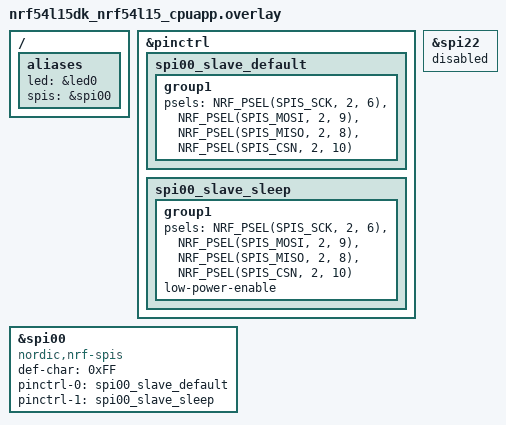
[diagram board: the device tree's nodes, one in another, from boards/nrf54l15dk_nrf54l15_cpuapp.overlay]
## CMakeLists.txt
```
#
# Copyright (c) 2025 Nordic Semiconductor ASA
# SPDX-License-Identifier: LicenseRef-Nordic-5-Clause
#

cmake_minimum_required(VERSION 3.20.0)

find_package(Zephyr REQUIRED HINTS $ENV{ZEPHYR_BASE})

if(NOT SYSBUILD)
  message(FATAL_ERROR
    " This is a multi-image application that should be built using sysbuild.\n"
    " Add --sysbuild argument to west build command to prepare all the images."
  )
endif()

project(NRF54l15)

# Windows Device Guard workaround:
# Build static libraries with "ar qcs" and skip the separate ranlib step.
# This avoids calling arm-zephyr-eabi-ranlib.exe when it is policy-blocked.
if(WIN32)
  set(CMAKE_C_ARCHIVE_CREATE
      "<CMAKE_AR> qcs <TARGET> <LINK_FLAGS> <OBJECTS>"
      CACHE STRING "Create C static archive without separate ranlib" FORCE)
  set(CMAKE_CXX_ARCHIVE_CREATE
      "<CMAKE_AR> qcs <TARGET> <LINK_FLAGS> <OBJECTS>"
      CACHE STRING "Create CXX static archive without separate ranlib" FORCE)
  set(CMAKE_ASM_ARCHIVE_CREATE
      "<CMAKE_AR> qcs <TARGET> <LINK_FLAGS> <OBJECTS>"
      CACHE STRING "Create ASM static archive without separate ranlib" FORCE)

  set(CMAKE_C_ARCHIVE_FINISH "" CACHE STRING "Skip C ranlib step" FORCE)
  set(CMAKE_CXX_ARCHIVE_FINISH "" CACHE STRING "Skip CXX ranlib step" FORCE)
  set(CMAKE_ASM_ARCHIVE_FINISH "" CACHE STRING "Skip ASM ranlib step" FORCE)
endif()

target_sources(app PRIVATE
  ${CMAKE_CURRENT_SOURCE_DIR}/src/main.c
)
```

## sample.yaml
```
common:
  sysbuild: true
  depends_on: spi

sample:
  name: SPI wakeup sample
tests:
  nrf.extended.sample.drivers.spis.wakeup:
    tags:
      - ci_samples_zephyr_boards_nordic_spis_wakeup
      - spi
      - ppk_power_measure
    platform_allow:
      - nrf54h20dk/nrf54h20/cpuapp
      - nrf54l15dk/nrf54l15/cpuapp
    integration_platforms:
      - nrf54h20dk/nrf54h20/cpuapp
      - nrf54l15dk/nrf54l15/cpuapp
    harness: pytest
    harness_config:
      fixture: spi_loopback
      pytest_root:
        - "${CUSTOM_ROOT_TEST_DIR}/test_measure_power_consumption.py::test_measure_and_data_dump_spis_wakeup"
```

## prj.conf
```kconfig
CONFIG_SPI=y
CONFIG_SPI_SLAVE=y
CONFIG_GPIO=y

# Bring-up/debug profile first. Re-enable PM once SPI link is validated.
CONFIG_PM=n
CONFIG_PM_DEVICE=n
CONFIG_PM_DEVICE_RUNTIME=n

CONFIG_ASSERT=y

CONFIG_PRINTK=y
CONFIG_LOG=y
CONFIG_LOG_MODE_IMMEDIATE=y
CONFIG_LOG_DEFAULT_LEVEL=3
CONFIG_CONSOLE=y
CONFIG_SERIAL=y

# Route console/log output over SEGGER RTT (instead of UART)
CONFIG_USE_SEGGER_RTT=y
CONFIG_RTT_CONSOLE=y
CONFIG_UART_CONSOLE=n
CONFIG_LOG_BACKEND_RTT=y
CONFIG_LOG_BACKEND_UART=n
```

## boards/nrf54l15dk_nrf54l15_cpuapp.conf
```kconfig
# nRF54L15 DK CPUAPP board-specific config for SPI slave bring-up.
# Keep empty for now; app-level settings are in prj.conf.
```

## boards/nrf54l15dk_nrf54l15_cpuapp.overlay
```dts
/*
 * nRF54L15 DK CPUAPP SPI-slave overlay — HSSPI (SPIS00, P2 port, up to 32 MHz).
 * Wire to Pico: GPIO18(SCK)→P2.06, GPIO19(MOSI)→P2.09, GPIO20(MISO)→P2.08, GPIO22(CS)→P2.10
 */

/ {
	aliases {
		led = &led0;
		spis = &spi00;               /* switched from spi22 to HSSPI instance */
		/delete-property/ led1;
		/delete-property/ mcuboot-button0;
	};
};

/delete-node/ &led1;

&pinctrl {
	spi00_slave_default: spi00_slave_default {
		group1 {
			psels = <NRF_PSEL(SPIS_SCK,  2, 6)>,
				<NRF_PSEL(SPIS_MOSI, 2, 9)>,
				<NRF_PSEL(SPIS_MISO, 2, 8)>,
				<NRF_PSEL(SPIS_CSN,  2, 10)>;
		};
	};

	spi00_slave_sleep: spi00_slave_sleep {
		group1 {
			psels = <NRF_PSEL(SPIS_SCK,  2, 6)>,
				<NRF_PSEL(SPIS_MOSI, 2, 9)>,
				<NRF_PSEL(SPIS_MISO, 2, 8)>,
				<NRF_PSEL(SPIS_CSN,  2, 10)>;
			low-power-enable;
		};
	};
};

&spi00 {
	compatible = "nordic,nrf-spis";
	status = "okay";
	/delete-property/ cs-gpios;
	/delete-property/ rx-delay-supported;
	/delete-property/ rx-delay;
	def-char = <0xFF>;
	pinctrl-0 = <&spi00_slave_default>;
	pinctrl-1 = <&spi00_slave_sleep>;
	pinctrl-names = "default", "sleep";
	/delete-node/ mx25r6435f@0;
};

/* Disable the old spi22 slave to release P1 pins */
&spi22 {
	status = "disabled";
};
```

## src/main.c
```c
/*
 * Copyright (c) 2025 Nordic Semiconductor ASA
 * SPDX-License-Identifier: Apache-2.0
 */

#include <zephyr/kernel.h>
#include <zephyr/logging/log.h>
#include <zephyr/drivers/spi.h>
#include <zephyr/drivers/gpio.h>
#include <string.h>

#define NRF_BENCH_MODE  // Compile with this defined to enable the SPI slave test mode that logs transfer stats and button events; undefine for production build without logging and NRF event handling

#define BUF_SIZE 4096

static const struct device *spis_dev = DEVICE_DT_GET(DT_ALIAS(spis));
static const struct spi_config spis_config = {.operation = SPI_OP_MODE_SLAVE | SPI_WORD_SET(8) | SPI_MODE_CPHA};

#ifdef NRF_BENCH_MODE

#define BUTTON_DEBOUNCE_SAMPLES 4
#define BUTTON_RETRIGGER_GUARD_MS 350

static const struct gpio_dt_spec led = GPIO_DT_SPEC_GET(DT_ALIAS(led), gpios);
static const struct gpio_dt_spec btn0 = GPIO_DT_SPEC_GET(DT_ALIAS(sw0), gpios);
static const struct gpio_dt_spec btn1 = GPIO_DT_SPEC_GET(DT_ALIAS(sw1), gpios);
static const struct gpio_dt_spec btn2 = GPIO_DT_SPEC_GET(DT_ALIAS(sw2), gpios);
static const struct gpio_dt_spec btn3 = GPIO_DT_SPEC_GET(DT_ALIAS(sw3), gpios);

LOG_MODULE_REGISTER(spi_slave_test, LOG_LEVEL_INF);

static uint8_t tx_buffer[BUF_SIZE];
static uint8_t rx_buffer[BUF_SIZE];
static uint8_t pending_button_events;
static uint8_t debounced_button_state;
static uint8_t button_change_count[4];
static int64_t button_next_press_ok_ms[4];
static uint32_t transfer_count;
static uint32_t error_count;
static uint32_t zero_frame_count;
static uint32_t short_frame_count;
static uint32_t marker_inject_count;
static uint8_t last_rx0;
static uint8_t last_rx1;
static uint8_t last_rx2;
static uint8_t last_rx3;
static uint8_t last_rx13;
static uint8_t last_rx14;

static void fill_tx_pattern(void)
{
	for (size_t i = 0; i < BUF_SIZE; ++i) {
		tx_buffer[i] = (i & 1u) ? 0xA5 : 0x5A;
	}
}

static uint8_t xor_checksum(const uint8_t *buf, size_t len)
{
	uint8_t x = 0;
	for (size_t i = 0; i < len; ++i) {
		x ^= buf[i];
	}
	return x;
}

static bool buffer_all_value(const uint8_t *buf, size_t len, uint8_t value)
{
	for (size_t i = 0; i < len; ++i) {
		if (buf[i] != value) {
			return false;
		}
	}
	return true;
}

static uint8_t read_button_state(void)
{
	uint8_t state = 0;
	/* Active-low buttons: pressed => bit set in returned mask. */
	if (gpio_pin_get_dt(&btn0) == 0) state |= BIT(0);
	if (gpio_pin_get_dt(&btn1) == 0) state |= BIT(1);
	if (gpio_pin_get_dt(&btn2) == 0) state |= BIT(2);
	if (gpio_pin_get_dt(&btn3) == 0) state |= BIT(3);
	return state;
}

static void update_button_events(void)
{
	uint8_t raw = read_button_state();
	uint8_t rising_press = 0;
	int64_t now_ms = k_uptime_get();

	for (uint8_t i = 0; i < 4; ++i) {
		uint8_t bit = BIT(i);
		bool raw_pressed = (raw & bit) != 0;
		bool stable_pressed = (debounced_button_state & bit) != 0;

		if (raw_pressed == stable_pressed) {
			button_change_count[i] = 0;
			continue;
		}

		if (button_change_count[i] < 0xFF) {
			button_change_count[i]++;
		}
		if (button_change_count[i] < BUTTON_DEBOUNCE_SAMPLES) {
			continue;
		}

		button_change_count[i] = 0;
		if (raw_pressed) {
			debounced_button_state |= bit;
			if (now_ms >= button_next_press_ok_ms[i]) {
				rising_press |= bit;
				button_next_press_ok_ms[i] = now_ms + BUTTON_RETRIGGER_GUARD_MS;
			}
		} else {
			debounced_button_state &= (uint8_t)~bit;
		}
	}

	if (rising_press != 0) {
		LOG_INF("buttons rising=0x%02X raw=0x%02X stable=0x%02X", rising_press, raw, debounced_button_state);
	}
	pending_button_events |= rising_press;
}

int main(void)
{
	int status;
	uint32_t frame_count = 0;
	struct spi_buf tx_spi_buf = {.buf = tx_buffer, .len = sizeof(tx_buffer)};
	struct spi_buf rx_spi_buf = {.buf = rx_buffer, .len = sizeof(rx_buffer)};
	struct spi_buf_set tx_set = {.buffers = &tx_spi_buf, .count = 1};
	struct spi_buf_set rx_set = {.buffers = &rx_spi_buf, .count = 1};

	LOG_INF("Hello world from %s", CONFIG_BOARD_TARGET);

	status = gpio_is_ready_dt(&led);
	__ASSERT(status, "Error: GPIO Device not ready");

	status = gpio_pin_configure_dt(&led, GPIO_OUTPUT_ACTIVE);
	__ASSERT(status == 0, "Could not configure led GPIO");

	status = gpio_is_ready_dt(&btn0);
	__ASSERT(status, "Button0 GPIO not ready");
	status = gpio_is_ready_dt(&btn1);
	__ASSERT(status, "Button1 GPIO not ready");
	status = gpio_is_ready_dt(&btn2);
	__ASSERT(status, "Button2 GPIO not ready");
	status = gpio_is_ready_dt(&btn3);
	__ASSERT(status, "Button3 GPIO not ready");

	status = gpio_pin_configure_dt(&btn0, GPIO_INPUT | GPIO_PULL_UP);
	__ASSERT(status == 0, "Could not configure button0 GPIO");
	status = gpio_pin_configure_dt(&btn1, GPIO_INPUT | GPIO_PULL_UP);
	__ASSERT(status == 0, "Could not configure button1 GPIO");
	status = gpio_pin_configure_dt(&btn2, GPIO_INPUT | GPIO_PULL_UP);
	__ASSERT(status == 0, "Could not configure button2 GPIO");
	status = gpio_pin_configure_dt(&btn3, GPIO_INPUT | GPIO_PULL_UP);
	__ASSERT(status == 0, "Could not configure button3 GPIO");

	status = device_is_ready(spis_dev);
	__ASSERT(status, "Error: SPI device is not ready");

	fill_tx_pattern();
	LOG_INF("TX pattern[0..3]=%02X %02X %02X %02X",
		tx_buffer[0], tx_buffer[1], tx_buffer[2], tx_buffer[3]);
	LOG_INF("diag: BUF_SIZE=%u, SPI slave 8-bit Mode1 (CPHA=1), button aliases sw0..sw3 enabled", BUF_SIZE);
	debounced_button_state = read_button_state();
	memset(button_change_count, 0, sizeof(button_change_count));
	for (size_t i = 0; i < 4; ++i) {
		button_next_press_ok_ms[i] = 0;
	}
	pending_button_events = 0;
	LOG_INF("buttons initial=0x%02X", debounced_button_state);

	size_t prev_frame_len = sizeof(rx_buffer); /* start safe: full clear on first iteration */
	while (1) {
		/* Clear only as many bytes as the previous transfer received.
		 * Clearing all 4096 bytes on every 4-byte benchmark frame added ~300 µs of
		 * dead time between spi_transceive calls, causing the Pico to fire again
		 * before the slave re-armed (50 % failure with 200 µs gap). */
		memset(rx_buffer, 0x00, prev_frame_len);
		gpio_pin_set_dt(&led, 0);
		int ret = spi_transceive(spis_dev, &spis_config, &tx_set, &rx_set);
		gpio_pin_set_dt(&led, 1);

		/* In Zephyr slave mode, spi_transceive() returns number of received frames on success. */
		if (ret < 0) {
			error_count++;
			LOG_ERR("spi_transceive failed: %d", ret);
			k_msleep(10);
			continue;
		}

		transfer_count++;
		if (ret == 0) {
			zero_frame_count++;
		}
		if (ret > 0 && ret < 8) {
			short_frame_count++;
		}

		if (ret > 0) {
			prev_frame_len = (size_t)ret;
			update_button_events();
			memcpy(tx_buffer, rx_buffer, (size_t)ret);
			last_rx0 = rx_buffer[0];
			last_rx1 = (ret > 1) ? rx_buffer[1] : 0;
			last_rx2 = (ret > 2) ? rx_buffer[2] : 0;
			last_rx3 = (ret > 3) ? rx_buffer[3] : 0;
			last_rx13 = (ret > 13) ? rx_buffer[13] : 0;
			last_rx14 = (ret > 14) ? rx_buffer[14] : 0;
			if (pending_button_events != 0 && ret >= 2) {
				/* Inject one-shot event marker in next transfer payload. */
				tx_buffer[0] = 0xA5;
				tx_buffer[1] = pending_button_events;
				marker_inject_count++;
				LOG_INF("inject marker: evt=0x%02X count=%u ret=%d", pending_button_events, marker_inject_count, ret);
				pending_button_events = 0;
			}
		}

		frame_count++;
		if ((frame_count % 200u) == 0u) {
			uint8_t chk = xor_checksum(rx_buffer, (ret > 0) ? (size_t)ret : sizeof(rx_buffer));
			bool all_ff = (ret > 0) ? buffer_all_value(rx_buffer, (size_t)ret, 0xFF) : false;
			bool all_00 = (ret > 0) ? buffer_all_value(rx_buffer, (size_t)ret, 0x00) : false;
			LOG_INF("count=%u ret=%d RX[0..3]=%02X %02X %02X %02X RX[13..14]=%02X %02X xor=%02X pend=0x%02X err=%u zero=%u short=%u marker=%u all00=%u allFF=%u",
				frame_count, ret, last_rx0, last_rx1, last_rx2, last_rx3, last_rx13, last_rx14, chk, pending_button_events,
				error_count, zero_frame_count, short_frame_count, marker_inject_count,
				all_00 ? 1u : 0u, all_ff ? 1u : 0u);
		}
	}

	return 0;
}

#else /* NRF_BENCH_MODE not defined — production build */

LOG_MODULE_REGISTER(nrf_spis, LOG_LEVEL_INF);

static uint8_t tx_buffer[BUF_SIZE];
static uint8_t rx_buffer[BUF_SIZE];

int main(void)
{
	struct spi_buf tx_spi_buf = {.buf = tx_buffer, .len = sizeof(tx_buffer)};
	struct spi_buf rx_spi_buf = {.buf = rx_buffer, .len = sizeof(rx_buffer)};
	struct spi_buf_set tx_set = {.buffers = &tx_spi_buf, .count = 1};
	struct spi_buf_set rx_set = {.buffers = &rx_spi_buf, .count = 1};

	__ASSERT(device_is_ready(spis_dev), "SPI device not ready");

	LOG_INF("nRF54L15 SPIS ready (production build, Mode 1, %u B buffer)", BUF_SIZE);

	while (1) {
		/* TODO: production logic — fill tx_buffer with FFT/audio results,
		 * then block here until the RP master completes a transfer. */
		int ret = spi_transceive(spis_dev, &spis_config, &tx_set, &rx_set);
		if (ret < 0) {
			LOG_ERR("spi_transceive failed: %d", ret);
			k_msleep(10);
		}
	}

	return 0;
}

#endif /* NRF_BENCH_MODE */
```
